# MCXN947_cm33_core0 register map
Vendor: nxp.com; File version: 1.0
CPU: CM33 r2p0, little endian, MPU, FPU, VTOR, 3 interrupt priority bits
Registers are 32-bit, read-write, reset 0x0 unless marked. A register's access mark holds for its fields unless they carry their own. Offsets are from the block's base; [hi:lo] are bit positions; {n}, {i} and the like mark numbered series; 'fields as' and 'values as' point back to an identical list.

## ADC0 — ADC
Base 0x4010D000
Same registers: ADC1 0x4010E000
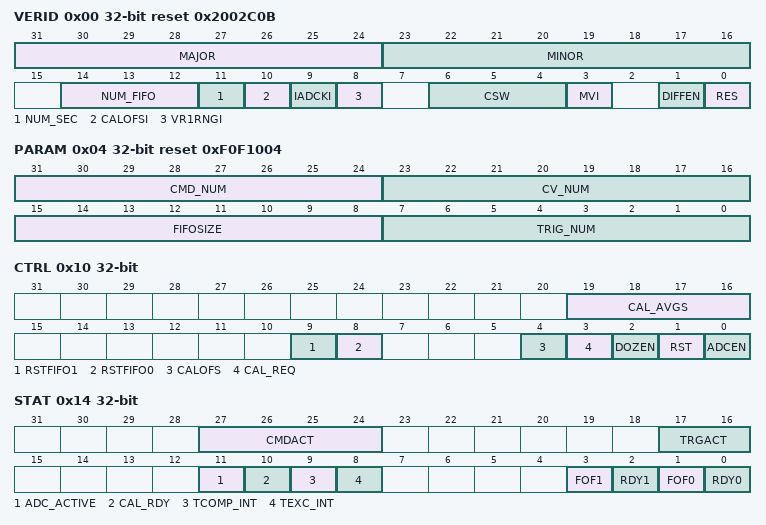
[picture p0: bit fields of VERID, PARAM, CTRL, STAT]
0x00 VERID ro reset 0x2002C0B — Version ID Register
  [31:24] MAJOR — Major Version Number
  [23:16] MINOR — Minor Version Number
  [14:12] NUM_FIFO — Number of FIFOs
    0=NO_FIFO_IMPLEMENTED (N/A); 1=CNT_1 (One); 2=CNT_2 (Two); 3=CNT_3 (Three); 4=CNT_4 (Four)
  [11] NUM_SEC — Number of Single-Ended Outputs Supported
    0=SINGLE_CONVERTOR (One); 1=DUAL_CONVERTOR (Two)
  [10] CALOFSI — Calibration Function Implemented
    0=CAL_FUNCTION_NOT_AVAILABLE (Not implemented); 1=CAL_FUNCTION_AVAILABLE (Implemented)
  [9] IADCKI — Internal ADC Clock Implemented
    0=INTERNAL_CLK_NOT_AVAILABLE (Not implemented); 1=INTERNAL_CLK_AVAILABLE (Implemented)
  [8] VR1RNGI — Voltage Reference 1 Range Control Bit Implemented
    0=REF1_FIXED_VOLTAGE_RANGE (Range control not required.); 1=REF1_SELECTABLE_VOLTAGE_RANGE (Range control required.)
  [6:4] CSW — Channel Scale Width
    0=CSCALE_NOT_SUPPORTED (Not supported.); 1=BIT_WIDTH_1 (Supported with one-bit CSCALE control field.); 6=BIT_WIDTH_6 (Supported with six-bit CSCALE control field.)
  [3] MVI — Multiple Vref Implemented
    0=MULTIPLE_REF_NOT_SUPPORTED (Single VREFH input supported.); 1=MULTIPLE_REF_SUPPORTED (Multiple VREFH inputs supported.)
  [1] DIFFEN — Differential Supported
    0=DIFFERENTIAL_NOT_SUPPORTED (Not supported); 1=DIFFERENTIAL_SUPPORTED (Supported. CMDLn[CTYPE] controls fields implemented.)
  [0] RES — Resolution
    0=MAX_13_bit (Up to 13-bit differential or 12-bit single-ended resolution supported.); 1=MAX_16_bit (Up to 16-bit differential or 16-bit single-ended resolution supported. CMDLn[MODE] available for selecting the resolution of conversions for the associated command.)
0x04 PARAM ro reset 0xF0F1004 — Parameter Register
  [31:24] CMD_NUM — Command Buffer Number
  [23:16] CV_NUM — Compare Value Number
  [15:8] FIFOSIZE — Result FIFO Depth
    1=ENTRIES_2 (2); 4=ENTRIES_4 (4); 8=ENTRIES_8 (8); 16=ENTRIES_16 (16); 32=ENTRIES_32 (32); 64=ENTRIES_64 (64)
  [7:0] TRIG_NUM — Trigger Number
0x10 CTRL — Control Register
  [19:16] CAL_AVGS — Auto-Calibration Averages
    0=NO_AVERAGE (Single conversion.); 1=AVERAGE_2 (2 conversions averaged.); 2=AVERAGE_4 (4 conversions averaged.); 3=AVERAGE_8 (8 conversions averaged.); 4=AVERAGE_16 (16 conversions averaged.); 5=AVERAGE_32 (32 conversions averaged.); 6=AVERAGE_64 (64 conversions averaged.); 7=AVERAGE_128 (128 conversions averaged.); 8=AVERAGE_256 (256 conversions averaged.); 9=AVERAGE_512 (512 conversions averaged.); 10=AVERAGE_1024 (1024 conversions averaged.)
  [9] RSTFIFO1 — Reset FIFO 1
    0=NO_ACTION (No effect.); 1=TRIGGER_RESET (FIFO 1 is reset.)
  [8] RSTFIFO0 — Reset FIFO 0
    0=NO_ACTION (No effect.); 1=TRIGGER_RESET (FIFO 0 is reset.)
  [4] CALOFS — Offset Calibration Request
    0=NO_ACTIVE_OFFSET_CALIBRATION_REQUEST (Calibration function disabled); 1=OFFSET_CALIBRATION_REQUEST_PENDING (Request for offset calibration function)
  [3] CAL_REQ — Auto-Calibration Request
    0=NO_CALIBRATION_REQUEST (No request made.); 1=CALIBRATION_REQUEST_PENDING (Request has been made.)
  [2] DOZEN — Doze Enable
    0=ENABLED (ADC is enabled in low-power mode.); 1=DISABLED (ADC is disabled in low-power mode.)
  [1] RST — Software Reset
    0=RELEASED_FROM_RESET (ADC logic is not reset.); 1=HELD_IN_RESET (ADC logic is reset.)
  [0] ADCEN — ADC Enable
    0=DISABLED; 1=ENABLED
0x14 STAT — Status Register
  [27:24] CMDACT ro — Command Active
    0=NO_COMMAND_ACTIVE (No command currently in progress.); 1=COMMAND_1 (Command 1 currently being executed.); 2=COMMAND_2 (Command 2 currently being executed.); {v}=COMMAND_x_{v} (Associated command number currently being executed.) (v=3..9)
  [17:16] TRGACT ro — Trigger Active
    {v}=TRIG_{v} (Command (sequence) associated with Trigger {v} currently being executed.) (v=0..3)
  [11] ADC_ACTIVE ro
    0=NOT_ACTIVE (ADC is idle. There are no pending triggers to service and no active commands are being processed.); 1=BUSY (ADC is processing a conversion, running through the power-up delay, or servicing a trigger.)
  [10] CAL_RDY ro — Calibration Ready
    0=NOT_SET (Calibration is incomplete or has not been run.); 1=HARDWARE_CAL_STEP_COMPLETED (ADC is calibrated.)
  [9] TCOMP_INT write-1-clears — Interrupt Flag For Trigger Completion
    0=FLAG_CLEAR (Either IE[TCOMP_IE] = 0, or no trigger sequences have run to completion.); 1=COMPLETION_DETECTED (Trigger sequence has been completed and all data is stored in the associated FIFO.)
  [8] TEXC_INT write-1-clears — Interrupt Flag For High-Priority Trigger Exception
    0=NO_EXCEPTION (No trigger exceptions have occurred.); 1=EXCEPTION_DETECTED (A trigger exception has occurred and is pending acknowledgment.)
  [3] FOF1 write-1-clears — Result FIFO1 Overflow Flag
    0=NO_OVERFLOW (No result FIFO1 overflow has occurred since the last time that the flag was cleared.); 1=OVERFLOW_DETECTED (At least one result FIFO1 overflow has occurred since the last time that the flag was cleared.)
  [2] RDY1 ro — Result FIFO1 Ready Flag
    0=BELOW_THRESHOLD (Not above watermark); 1=ABOVE_THRESHOLD (Above watermark)
  [1] FOF0 write-1-clears — Result FIFO 0 Overflow Flag
    0=NO_OVERFLOW (No result FIFO 0 overflow has occurred since the last time that the flag was cleared.); 1=OVERFLOW_DETECTED (At least one result FIFO 0 overflow has occurred since the last time that the flag was cleared.)
  [0] RDY0 ro — Result FIFO 0 Ready Flag
    values as RDY1
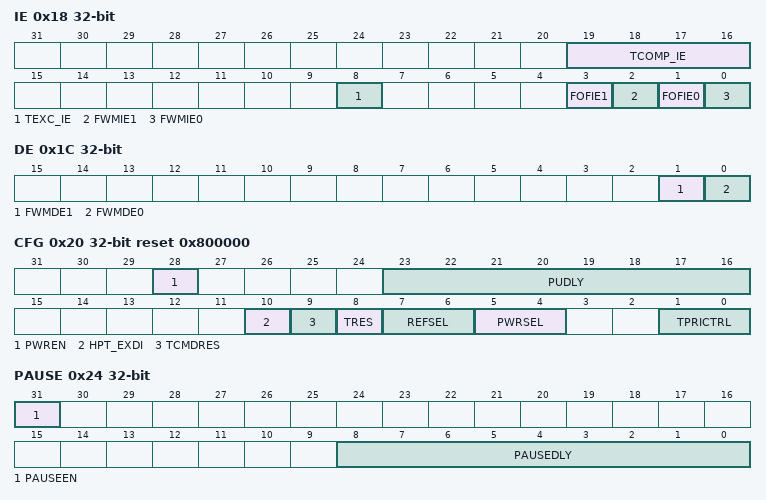
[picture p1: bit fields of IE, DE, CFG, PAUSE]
0x18 IE — Interrupt Enable Register
  [19:16] TCOMP_IE — Trigger Completion Interrupt Enable
    0=DISABLED (All disabled); 1=TRIGGER_0_COMPLETE_ENABLED (Trigger completion interrupts are enabled for trigger source 0 only.); 2=TRIGGER_1_COMPLETE_ENABLED (Trigger completion interrupts are enabled for trigger source 1 only.); {v}=TRIGGER_x_COMPLETE_ENABLED_{v} (Associated trigger completion interrupts are enabled.) (v=3..9); 15=ALL_TRIGGER_COMPLETES_ENABLED (All enabled)
  [8] TEXC_IE — Trigger Exception Interrupt Enable
    0=DISABLED; 1=ENABLED
  [3] FOFIE1 — Result FIFO1 Overflow Interrupt Enable
    0=DISABLED; 1=ENABLED
  [2] FWMIE1 — FIFO1 Watermark Interrupt Enable
    0=DISABLED; 1=ENABLED
  [1] FOFIE0 — Result FIFO 0 Overflow Interrupt Enable
    0=DISABLED; 1=ENABLED
  [0] FWMIE0 — FIFO 0 Watermark Interrupt Enable
    0=DISABLED; 1=ENABLED
0x1C DE — DMA Enable Register
  [1] FWMDE1 — FIFO1 Watermark DMA Enable
    0=DISABLED; 1=ENABLED
  [0] FWMDE0 — FIFO 0 Watermark DMA Enable
    0=DISABLED; 1=ENABLED
0x20 CFG reset 0x800000 — Configuration Register
  [28] PWREN — ADC Analog Pre-Enable
    0=NOT_PRE_ENABLED (ADC analog circuits are only enabled while conversions are active. Analog startup delays affect performance.); 1=PRE_ENABLED (ADC analog circuits are pre-enabled and ready to execute conversions without startup delays, at the cost of higher DC current consumption. A single power-up delay (CFG[PUDLY]) is executed immediately once PWREN is set. No detected triggers begin ADC operation until the power-up delay time has passed. After this initial delay expires, the analog circuits remain pre-enabled, and no additional delays are executed.)
  [23:16] PUDLY — Power-up Delay
  [10] HPT_EXDI — High-Priority Trigger Exception Disable
    0=ENABLED; 1=DISABLED
  [9] TCMDRES — Trigger Command Resume
    0=DISABLED (Trigger sequence automatically restarted.); 1=ENABLED (Trigger sequence resumed from the command that was executed prior to the exception.)
  [8] TRES — Trigger Resume Enable
    0=DISABLED (Not automatically resumed or restarted); 1=ENABLED (Automatically resumed or restarted)
  [7:6] REFSEL — Voltage Reference Selection
    0=OPTION_1; 1=OPTION_2; 2=OPTION_3
  [5:4] PWRSEL — Power Configuration Select
    0b0x=LOWEST (Low power); 0b1x=HIGHEST (High power)
  [1:0] TPRICTRL — ADC Trigger Priority Control
    0=ABORT_CURRENT_ON_PRIORITY (Current conversion is aborted and the new command specified by the trigger is started.); 1=FINISH_CURRENT_ON_PRIORITY (Current command is stopped after completing the current conversion. If averaging is enabled, the averaging loop is completed. CMDHn[LOOP] is ignored and the higher-priority trigger is serviced.); 2=FINISH_SEQUENCE_ON_PRIORITY (Current command is completed (averaging, looping, compare) before servicing the higher-priority trigger.)
0x24 PAUSE
  [31] PAUSEEN — Pause Enable
    0=DISABLED; 1=ENABLED
  [8:0] PAUSEDLY — Pause Delay
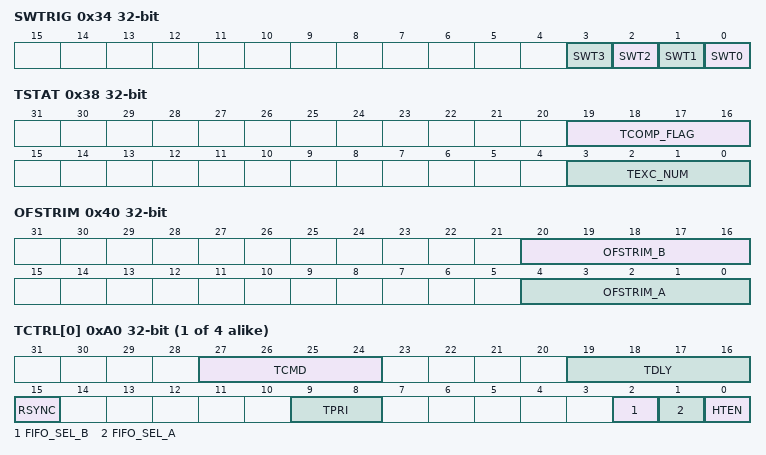
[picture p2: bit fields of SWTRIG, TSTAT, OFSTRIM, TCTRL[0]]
0x34 SWTRIG — Software Trigger Register
  [n] SWT{n} (n=0..3) — Software Trigger {n}
    0=NO_TRIGGER (No trigger {n} event generated.); 1=INITIATE_TRIGGER_{n} (Trigger {n} event generated.)
0x38 TSTAT write-1-clears — Trigger Status Register
  [19:16] TCOMP_FLAG write-1-clears — Trigger Completion Flag
    0=NO_TRIGGER (No triggers have been completed. Trigger completion interrupts are disabled.); 1=BIT0_MEANS_TRIGGER_0_COMPLETED (Trigger 0 has been completed and trigger 0 has enabled completion interrupts.); 2=BIT1_MEANS_TRIGGER_1_COMPLETED (Trigger 1 has been completed and trigger 1 has enabled completion interrupts.); {v}=SET_BITS_INDICATE_TRIGGER_x_COMPLETED_{v} (Associated trigger sequence has completed and has enabled completion interrupts.) (v=3..9); 15=ALL_BITS_SET_INDICATE_ALL_TRIGGERS_COMPLETED (Every trigger sequence has been completed and every trigger has enabled completion interrupts.)
  [3:0] TEXC_NUM write-1-clears — Trigger Exception Number
    0=NO_EXCEPTIONS (No triggers have been interrupted by a high-priority exception.); 1=BIT0_MEANS_TRIGGER_0_INTERRUPTED (Trigger 0 has been interrupted by a high-priority exception.); 2=BIT1_MEANS_TRIGGER_1_INTERRUPTED (Trigger 1 has been interrupted by a high-priority exception.); {v}=SET_BITS_INDICATE_TRIGGER_x_INTERRUPTED_{v} (Associated trigger sequence has interrupted by a high-priority exception.) (v=3..9); 15=ALL_BITS_SET_INDICATE_ALL_TRIGGERS_INTERRUPTED (Every trigger sequence has been interrupted by a high-priority exception.)
0x40 OFSTRIM — Offset Trim Register
  [20:16] OFSTRIM_B — Trim for Offset
  [4:0] OFSTRIM_A — Trim for Offset
{0xA0+4i} TCTRL[{i}] (i=0..3) — Trigger Control Register
  [27:24] TCMD — Trigger Command Select
    0=NOT_VALID (Not a valid selection from the command buffer. Trigger event is ignored.); 1=EXECUTE_CMD1 (CMD1); {v}=EXECUTE_CORRESPONDING_CMD_{v} (Corresponding CMD is executed) (v=2..9); 15=EXECUTE_CMD15 (CMD15)
  [19:16] TDLY — Trigger Delay Select
  [15] RSYNC — Trigger Resync
    0=DISABLE; 1=ENABLE
  [9:8] TPRI — Trigger Priority Setting
    0=HIGHEST_PRIORITY (Highest priority, Level 1); 1=CORRESPONDING_LOWER_PRIORITY_1 (Set to corresponding priority level.); 2=CORRESPONDING_LOWER_PRIORITY_2 (Set to corresponding priority level.); 3=LOWEST_PRIORITY (Lowest priority, Level 4)
  [2] FIFO_SEL_B — SAR Result Destination for Channel B
    0=STORE_TO_FIFO0 (FIFO 0); 1=STORE_TO_FIFO1 (FIFO 1)
  [1] FIFO_SEL_A — SAR Result Destination for Channel A
    0=STORE_TO_FIFO0 (FIFO 0); 1=STORE_TO_FIFO1 (FIFO 1)
  [0] HTEN — Trigger Enable
    0=DISABLED; 1=ENABLED
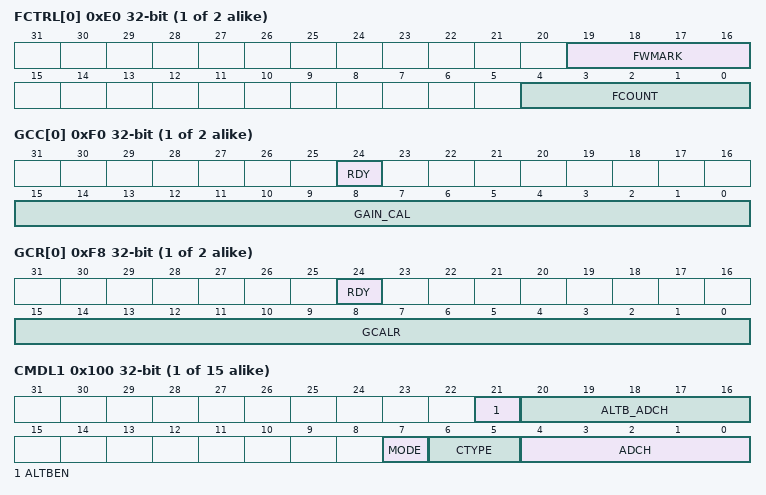
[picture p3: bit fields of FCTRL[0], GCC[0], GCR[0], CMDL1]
{0xE0+4i} FCTRL[{i}] (i=0..1) — FIFO Control Register
  [19:16] FWMARK — Watermark Level Selection
  [4:0] FCOUNT ro — Result FIFO Counter
{0xF0+4i} GCC[{i}] (i=0..1) ro — Gain Calibration Control
  [24] RDY — Gain Calibration Value Valid
    0=GAIN_CAL_NOT_VALID (Invalid); 1=HARDWARE_CAL_ROUTINE_COMPLETED (Valid)
  [15:0] GAIN_CAL — Gain Calibration Value
{0xF8+4i} GCR[{i}] (i=0..1) — Gain Calculation Result
  [24] RDY — Gain Calculation Ready
    0=NOT_VALID (Invalid); 1=VALID
  [15:0] GCALR — Gain Calculation Result
{0xF8+8i} CMDL{i} (i=1..15) — Command Low Buffer Register
  [21] ALTBEN — Alternate Channel B Select Enable
    0=DISABLED (ALTBEN_ADCH disabled. Channel-A and Channel-B inputs are selected based on ADCH settings.); 1=ENABLED (ALTBEN_ADCH enabled. Channel-A inputs are selected by ADCH setting and Channel-B inputs are selected by ALTB_ADCH setting.)
  [20:16] ALTB_ADCH — Alternate Channel B Input Channel Select
    {v}=SELECT_CH{v}B (v=0..3); {v}=SELECT_CORRESPONDING_CHnB_{v} (Select corresponding channel CHnB) (v=4..9); 30=SELECT_CH30B; 31=SELECT_CH31B
  [7] MODE — Select Resolution of Conversions
    0=DATA_12_BITS (Standard resolution. Single-ended 12-bit conversion; differential 13-bit conversion with 2's complement output.); 1=DATA_16_BITS (High resolution. Single-ended 16-bit conversion; differential 16-bit conversion with 2's complement output.)
  [6:5] CTYPE — Conversion Type
    0=SINGLE_ENDED_A_SIDE_CHANNEL (Single-Ended mode. Only A-side channel is converted.); 1=SINGLE_ENDED_B_SIDE_CHANNEL (Single-Ended mode. Only B-side channel is converted.); 2=DIFFERENTIAL_A_MINUS_B (Differential mode. A-B.); 3=DUAL_A_AND_B (Dual-Single-Ended mode. Both A-side and B-side channels are converted independently.)
  [4:0] ADCH — Input Channel Select
    {v}=SELECT_CH{v} (CH{v}A or CH{v}B or CH{v}A/CH{v}B pair.) (v=0..3); {v}=SELECT_CORRESPONDING_CHANNEL_{v} (Select corresponding channel CHnA or CHnB or CHnA/CHnB pair.) (v=4..9); 30=SELECT_CH30 (CH30A or CH30B or CH30A/CH30B pair.); 31=SELECT_CH31 (CH31A or CH31B or CH31A/CH31B pair.)
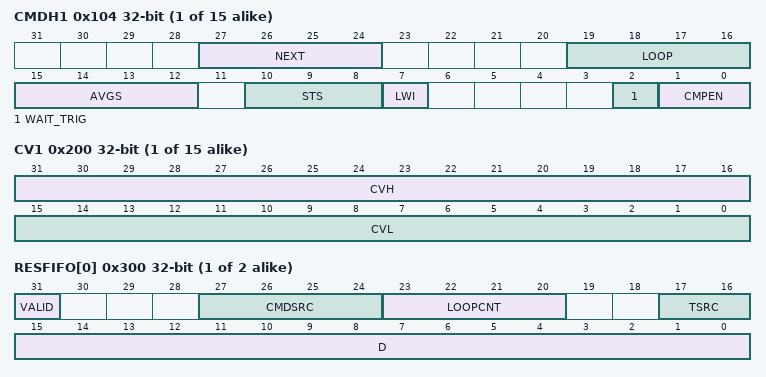
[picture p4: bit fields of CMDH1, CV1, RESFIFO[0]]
{0xFC+8i} CMDH{i} (i=1..15) — Command High Buffer Register
  [27:24] NEXT — Next Command Select
    0=NO_NEXT_CMD_TERMINATE_ON_FINISH (No next command defined. Terminate conversions at completion of current command. If lower priority trigger pending, begin command associated with lower priority trigger.); 1=DO_CMD1_NEXT (CMD1); {v}=DO_CORRESPONDING_CMD_NEXT_{v} (Select corresponding CMD command buffer register as next command) (v=2..9); 15=DO_CMD15_NEXT (CMD15)
  [19:16] LOOP — Loop Count Select
    0=CMD_EXEC_1x (Looping not enabled. Command executes one time.); 1=CMD_EXEC_2x (Loop one time. Command executes two times.); 2=CMD_EXEC_3x (Loop two times. Command executes three times.); {v}=CMD_EXECUTES_CORRESPONDING_TIMES_{v} (Loop corresponding number of times. Command executes LOOP + 1 times.) (v=3..9); 15=CMD_EXEC_15x (Loop 15 times. Command executes 16 times.)
  [15:12] AVGS — Hardware Average Select
    0=NO_AVERAGE (Single conversion); 1=AVERAGE_2 (2); 2=AVERAGE_4 (4); 3=AVERAGE_8 (8); 4=AVERAGE_16 (16); 5=AVERAGE_32 (32); 6=AVERAGE_64 (64); 7=AVERAGE_128 (128); 8=AVERAGE_256 (256); 9=AVERAGE_512 (512); 10=AVERAGE_1024 (1024)
  [10:8] STS — Sample Time Select
    0=SAMPLE_3p5 (Minimum sample time of 3.5 ADCK cycles.); 1=SAMPLE_5p5 (5.5 ADCK cycles); 2=SAMPLE_7p5 (7.5 ADCK cycles); 3=SAMPLE_11p5 (11.5 ADCK cycles); 4=SAMPLE_19p5 (19.5 ADCK cycles); 5=SAMPLE_35p5 (35.5 ADCK cycles); 6=SAMPLE_67p5 (67.5 ADCK cycles); 7=SAMPLE_131p5 (131.5 ADCK cycles)
  [7] LWI — Loop with Increment
    0=DISABLED; 1=ENABLED
  [2] WAIT_TRIG — Wait for Trigger Assertion Before Execution
    0=DISABLED (Command executes automatically.); 1=ENABLED (Active trigger must be asserted again before executing this command.)
  [1:0] CMPEN — Compare Function Enable
    0=DISABLED_ALWAYS_STORE_RESULT; 2=COMPARE_RESULT_STORE_IF_TRUE (Enabled. Store on true.); 3=COMPARE_RESULT_KEEP_CONVERTING_UNTIL_TRUE_STORE_IF_TRUE (Enabled. Repeat channel acquisition (sample, convert, and compare) until true.)
{0x1FC+4i} CV{i} (i=1..15) — Compare Value Register
  [31:16] CVH — Compare Value High
  [15:0] CVL — Compare Value Low
{0x300+4i} RESFIFO[{i}] (i=0..1) ro — Data Result FIFO Register
  [31] VALID — FIFO Entry is Valid
    0=NOT_VALID (FIFO is empty. Discard any read from RESFIFO.); 1=VALID (FIFO contains data. FIFO record read from RESFIFO is valid.)
  [27:24] CMDSRC — Command Buffer Source
    0=NOT_VALID (Not a valid value CMDSRC value for a data word in RESFIFO. 0h is only found in the initial FIFO state, prior to the storage of an ADC conversion result into a RESFIFO buffer.); 1=CMD1; {v}=CORRESPONDING_CMD_{v} (Corresponding command buffer used as control settings for this conversion.) (v=2..9); 15=CMD15
  [23:20] LOOPCNT — Loop Count Value
    0=RESULT_1 (Result is from initial conversion in command.); 1=RESULT_2 (Result is from second conversion in command.); {v}=CORRESPONDING_RESULT_{v} (Result is from (LOOPCNT + 1) conversion in command.) (v=2..9); 15=RESULT_16 (Result is from 16th conversion in command.)
  [17:16] TSRC — Trigger Source
    0=TRIGGER_0 (Trigger source 0); 1=TRIGGER_1 (Trigger source 1); 2=CORRESPONDING_TRIGGER_2 (Corresponding trigger source initiated this conversion.); 3=TRIGGER_3 (Trigger source 3)
  [15:0] D — Data Result
{0x400+4i} CAL_GAR[{i}] (i=0..32) — Calibration General A-Side Registers
  [10:0] CAL_GAR_VAL — Calibration General A Side Register Element
{0x500+4i} CAL_GBR[{i}] (i=0..32) — Calibration General B-Side Registers
  [10:0] CAL_GBR_VAL — Calibration General B Side Register Element
